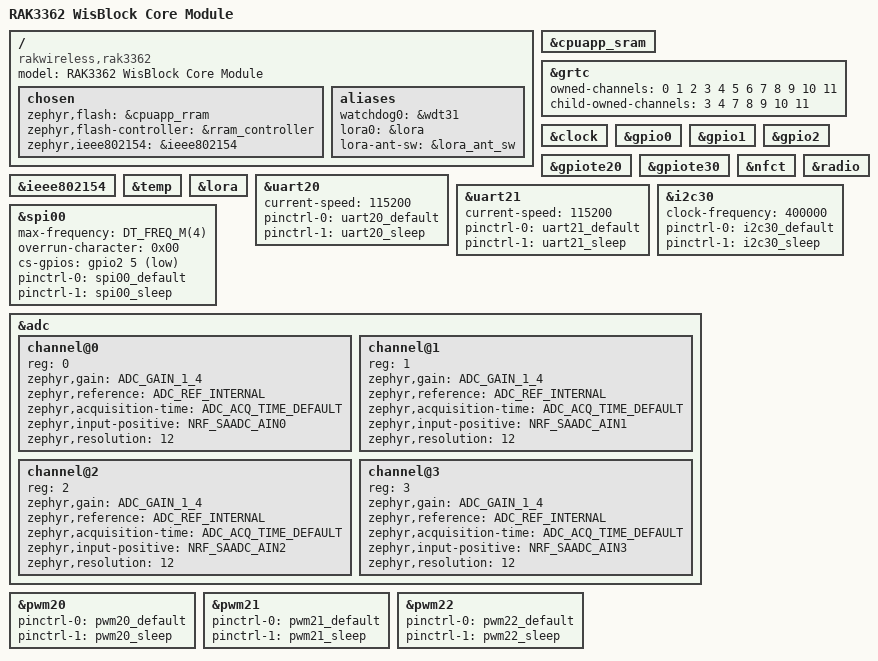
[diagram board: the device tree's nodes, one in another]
/*
 * Copyright (c) 2026 RAKwireless Technology Limited
 * SPDX-License-Identifier: Apache-2.0
 */

#include "rak3362-pinctrl.dtsi"

/ {
	model = "RAK3362 WisBlock Core Module";
	compatible = "rakwireless,rak3362";

	chosen {
		zephyr,flash = &cpuapp_rram;
		zephyr,flash-controller = &rram_controller;
		zephyr,ieee802154 = &ieee802154;
	};

	aliases {
		watchdog0 = &wdt31;
		lora0 = &lora;
		lora-ant-sw = &lora_ant_sw;
	};
};

&cpuapp_sram {
	status = "okay";
};

&grtc {
	owned-channels = <0 1 2 3 4 5 6 7 8 9 10 11>;
	/* Channels 7-11 reserved for Zero Latency IRQs; 3-4 for FLPR */
	child-owned-channels = <3 4 7 8 9 10 11>;
	status = "okay";
};

&clock {
	status = "okay";
};

&gpio0 {
	status = "okay";
};

&gpio1 {
	status = "okay";
};

&gpio2 {
	status = "okay";
};

&gpiote20 {
	status = "okay";
};

&gpiote30 {
	status = "okay";
};

&nfct {
	status = "okay";
};

&radio {
	status = "okay";
};

&ieee802154 {
	status = "okay";
};

&temp {
	status = "okay";
};

&lora {
	status = "okay";
};

/* WisBlock peripheral buses — pinctrl configured; status left to shield/application */

&uart20 {
	current-speed = <115200>;
	pinctrl-0 = <&uart20_default>;
	pinctrl-1 = <&uart20_sleep>;
	pinctrl-names = "default", "sleep";
};

&uart21 {
	current-speed = <115200>;
	pinctrl-0 = <&uart21_default>;
	pinctrl-1 = <&uart21_sleep>;
	pinctrl-names = "default", "sleep";
};

&i2c30 {
	clock-frequency = <400000>;
	pinctrl-0 = <&i2c30_default>;
	pinctrl-1 = <&i2c30_sleep>;
	pinctrl-names = "default", "sleep";
};

&spi00 {
	max-frequency = <DT_FREQ_M(4)>;
	overrun-character = <0x00>;
	cs-gpios = <&gpio2 5 GPIO_ACTIVE_LOW>;
	pinctrl-0 = <&spi00_default>;
	pinctrl-1 = <&spi00_sleep>;
	pinctrl-names = "default", "sleep";
};

&adc {
	status = "okay";
	#address-cells = <1>;
	#size-cells = <0>;

	channel@0 {
		reg = <0>;
		zephyr,gain = "ADC_GAIN_1_4";
		zephyr,reference = "ADC_REF_INTERNAL";
		zephyr,acquisition-time = <ADC_ACQ_TIME_DEFAULT>;
		zephyr,input-positive = <NRF_SAADC_AIN0>;
		zephyr,resolution = <12>;
	};

	channel@1 {
		reg = <1>;
		zephyr,gain = "ADC_GAIN_1_4";
		zephyr,reference = "ADC_REF_INTERNAL";
		zephyr,acquisition-time = <ADC_ACQ_TIME_DEFAULT>;
		zephyr,input-positive = <NRF_SAADC_AIN1>;
		zephyr,resolution = <12>;
	};

	channel@2 {
		reg = <2>;
		zephyr,gain = "ADC_GAIN_1_4";
		zephyr,reference = "ADC_REF_INTERNAL";
		zephyr,acquisition-time = <ADC_ACQ_TIME_DEFAULT>;
		zephyr,input-positive = <NRF_SAADC_AIN2>;
		zephyr,resolution = <12>;
	};

	channel@3 {
		reg = <3>;
		zephyr,gain = "ADC_GAIN_1_4";
		zephyr,reference = "ADC_REF_INTERNAL";
		zephyr,acquisition-time = <ADC_ACQ_TIME_DEFAULT>;
		zephyr,input-positive = <NRF_SAADC_AIN3>;
		zephyr,resolution = <12>;
	};
};

&pwm20 {
	status = "okay";
	pinctrl-0 = <&pwm20_default>;
	pinctrl-1 = <&pwm20_sleep>;
	pinctrl-names = "default", "sleep";
};

&pwm21 {
	status = "okay";
	pinctrl-0 = <&pwm21_default>;
	pinctrl-1 = <&pwm21_sleep>;
	pinctrl-names = "default", "sleep";
};

&pwm22 {
	status = "okay";
	pinctrl-0 = <&pwm22_default>;
	pinctrl-1 = <&pwm22_sleep>;
	pinctrl-names = "default", "sleep";
};

#include "wisblock.dtsi"
